AUTOSAR XML (schema 00046)
package /ComponentTypes
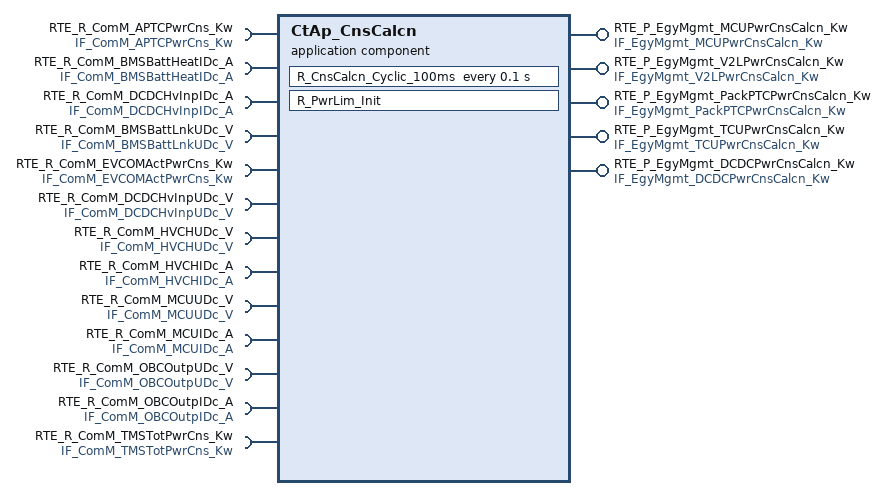
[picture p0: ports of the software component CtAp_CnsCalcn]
  application sw component type CtAp_CnsCalcn
    4 x provide port:
      RTE_P_EgyMgmt_MCUPwrCnsCalcn_Kw: nonqueued-sender-com-spec{data-element=tec_EgyMgmt_MCUPwrCnsCalcn_Kw, init-value=0}, provided-interface=IF_EgyMgmt_MCUPwrCnsCalcn_Kw
      RTE_P_EgyMgmt_V2LPwrCnsCalcn_Kw: nonqueued-sender-com-spec{data-element=IF_EgyMgmt_V2LPwrCnsCalcn_Kw, init-value=0}, provided-interface=IF_EgyMgmt_V2LPwrCnsCalcn_Kw
      RTE_P_EgyMgmt_PackPTCPwrCnsCalcn_Kw: nonqueued-sender-com-spec{data-element=tec_EgyMgmt_PackPTCPwrCnsCalcn_Kw, init-value=0}, provided-interface=IF_EgyMgmt_PackPTCPwrCnsCalcn_Kw
      RTE_P_EgyMgmt_TCUPwrCnsCalcn_Kw: nonqueued-sender-com-spec{data-element=tec_EgyMgmt_TCUPwrCnsCalcn_Kw, init-value=0}, provided-interface=IF_EgyMgmt_TCUPwrCnsCalcn_Kw
    13 x require port:
      RTE_R_ComM_APTCPwrCns_Kw: nonqueued-receiver-com-spec{data-element=tec_ComM_APTCPwrCns_Kw, filter=data-filter-type=ALWAYS, init-value=0}, required-interface=IF_ComM_APTCPwrCns_Kw
      RTE_R_ComM_BMSBattHeatIDc_A: nonqueued-receiver-com-spec{data-element=tec_ComM_BMSBattHeatIDc_A, filter=data-filter-type=ALWAYS, init-value=0}, required-interface=IF_ComM_BMSBattHeatIDc_A
      RTE_R_ComM_DCDCHvInpIDc_A: nonqueued-receiver-com-spec{data-element=tec_ComM_DCDCHvInpIDc_A, filter=data-filter-type=ALWAYS, init-value=0}, required-interface=IF_ComM_DCDCHvInpIDc_A
      RTE_R_ComM_BMSBattLnkUDc_V: nonqueued-receiver-com-spec{data-element=tec_ComM_BMSBattLnkUDc_V, filter=data-filter-type=ALWAYS, init-value=0}, required-interface=IF_ComM_BMSBattLnkUDc_V
      RTE_R_ComM_EVCOMActPwrCns_Kw: nonqueued-receiver-com-spec{data-element=tec_ComM_EVCOMActPwrCns_Kw, filter=data-filter-type=ALWAYS, init-value=0}, required-interface=IF_ComM_EVCOMActPwrCns_Kw
      RTE_R_ComM_DCDCHvInpUDc_V: nonqueued-receiver-com-spec{data-element=tec_ComM_DCDCHvInpUDc_V, filter=data-filter-type=ALWAYS, init-value=0}, required-interface=IF_ComM_DCDCHvInpUDc_V
      RTE_R_ComM_HVCHUDc_V: nonqueued-receiver-com-spec{data-element=tec_ComM_HVCHUDc_V, filter=data-filter-type=ALWAYS, init-value=0}, required-interface=IF_ComM_HVCHUDc_V
      RTE_R_ComM_HVCHIDc_A: nonqueued-receiver-com-spec{data-element=tec_ComM_HVCHIDc_A, filter=data-filter-type=ALWAYS, init-value=0}, required-interface=IF_ComM_HVCHIDc_A
      RTE_R_ComM_MCUUDc_V: nonqueued-receiver-com-spec{data-element=tec_ComM_MCUUDc_V, filter=data-filter-type=ALWAYS, init-value=0}, required-interface=IF_ComM_MCUUDc_V
      RTE_R_ComM_MCUIDc_A: nonqueued-receiver-com-spec{data-element=tec_ComM_MCUIDc_A, filter=data-filter-type=ALWAYS, init-value=0}, required-interface=IF_ComM_MCUIDc_A
      RTE_R_ComM_OBCOutpUDc_V: nonqueued-receiver-com-spec{data-element=tec_ComM_OBCOutpUDc_V, filter=data-filter-type=ALWAYS, init-value=0}, required-interface=IF_ComM_OBCOutpUDc_V
      RTE_R_ComM_OBCOutpIDc_A: nonqueued-receiver-com-spec{data-element=tec_ComM_OBCOutpIDc_A, filter=data-filter-type=ALWAYS, init-value=0}, required-interface=IF_ComM_OBCOutpIDc_A
      RTE_R_ComM_TMSTotPwrCns_Kw: nonqueued-receiver-com-spec{data-element=tec_ComM_TMSTotPwrCns_Kw, filter=data-filter-type=ALWAYS, init-value=0}, required-interface=IF_ComM_TMSTotPwrCns_Kw
    provide port RTE_P_EgyMgmt_DCDCPwrCnsCalcn_Kw: nonqueued-sender-com-spec{data-element=tec_EgyMgmt_DCDCPwrCnsCalcn_Kw, init-value=0}, provided-interface=IF_EgyMgmt_DCDCPwrCnsCalcn_Kw
    behavior CtAp_CnsCalcn_InternalBehavior
      init event CtAp_PwrLim_InitEvent: start-on-event=R_PwrLim_Init
      timing event TMT_R_CnsCalcn_Cyclic_100ms: start-on-event=R_CnsCalcn_Cyclic_100ms, period=0.1
      runnable R_PwrLim_Init
      runnable R_CnsCalcn_Cyclic_100ms
        data-receive-point-by-arguments:
          13 x access:
            REC_RTE_R_ComM_APTCPwrCns_Kw_tec_ComM_APTCPwrCns_Kw: accessed-variable=RTE_R_ComM_APTCPwrCns_Kw.tec_ComM_APTCPwrCns_Kw
            REC_RTE_R_ComM_BMSBattHeatIDc_A_tec_ComM_BMSBattHeatIDc_A: accessed-variable=RTE_R_ComM_BMSBattHeatIDc_A.tec_ComM_BMSBattHeatIDc_A
            REC_RTE_R_ComM_BMSBattLnkUDc_V_tec_ComM_BMSBattLnkUDc_V: accessed-variable=RTE_R_ComM_BMSBattLnkUDc_V.tec_ComM_BMSBattLnkUDc_V
            REC_RTE_R_ComM_DCDCHvInpIDc_A_tec_ComM_DCDCHvInpIDc_A: accessed-variable=RTE_R_ComM_DCDCHvInpIDc_A.tec_ComM_DCDCHvInpIDc_A
            REC_RTE_R_ComM_DCDCHvInpUDc_V_tec_ComM_DCDCHvInpUDc_V: accessed-variable=RTE_R_ComM_DCDCHvInpUDc_V.tec_ComM_DCDCHvInpUDc_V
            REC_RTE_R_ComM_EVCOMActPwrCns_Kw_tec_ComM_EVCOMActPwrCns_Kw: accessed-variable=RTE_R_ComM_EVCOMActPwrCns_Kw.tec_ComM_EVCOMActPwrCns_Kw
            REC_RTE_R_ComM_HVCHIDc_A_tec_ComM_HVCHIDc_A: accessed-variable=RTE_R_ComM_HVCHIDc_A.tec_ComM_HVCHIDc_A
            REC_RTE_R_ComM_HVCHUDc_V_tec_ComM_HVCHUDc_V: accessed-variable=RTE_R_ComM_HVCHUDc_V.tec_ComM_HVCHUDc_V
            REC_RTE_R_ComM_MCUIDc_A_tec_ComM_MCUIDc_A: accessed-variable=RTE_R_ComM_MCUIDc_A.tec_ComM_MCUIDc_A
            REC_RTE_R_ComM_MCUUDc_V_tec_ComM_MCUUDc_V: accessed-variable=RTE_R_ComM_MCUUDc_V.tec_ComM_MCUUDc_V
            REC_RTE_R_ComM_OBCOutpIDc_A_tec_ComM_OBCOutpIDc_A: accessed-variable=RTE_R_ComM_OBCOutpIDc_A.tec_ComM_OBCOutpIDc_A
            REC_RTE_R_ComM_OBCOutpUDc_V_tec_ComM_OBCOutpUDc_V: accessed-variable=RTE_R_ComM_OBCOutpUDc_V.tec_ComM_OBCOutpUDc_V
            REC_RTE_R_ComM_TMSTotPwrCns_Kw_tec_ComM_TMSTotPwrCns_Kw: accessed-variable=RTE_R_ComM_TMSTotPwrCns_Kw.tec_ComM_TMSTotPwrCns_Kw
        data-send-points:
          5 x access:
            SEND_RTE_P_EgyMgmt_DCDCPwrCnsCalcn_Kw_tec_EgyMgmt_DCDCPwrCnsCalcn_Kw: accessed-variable=RTE_P_EgyMgmt_DCDCPwrCnsCalcn_Kw.tec_EgyMgmt_DCDCPwrCnsCalcn_Kw
            SEND_RTE_P_EgyMgmt_MCUPwrCnsCalcn_Kw_tec_EgyMgmt_MCUPwrCnsCalcn_Kw: accessed-variable=RTE_P_EgyMgmt_MCUPwrCnsCalcn_Kw.tec_EgyMgmt_MCUPwrCnsCalcn_Kw
            SEND_RTE_P_EgyMgmt_PackPTCPwrCnsCalcn_Kw_tec_EgyMgmt_PackPTCPwrCnsCalcn_Kw: accessed-variable=RTE_P_EgyMgmt_PackPTCPwrCnsCalcn_Kw.tec_EgyMgmt_PackPTCPwrCnsCalcn_Kw
            SEND_RTE_P_EgyMgmt_TCUPwrCnsCalcn_Kw_tec_EgyMgmt_TCUPwrCnsCalcn_Kw: accessed-variable=RTE_P_EgyMgmt_TCUPwrCnsCalcn_Kw.tec_EgyMgmt_TCUPwrCnsCalcn_Kw
            SEND_RTE_P_EgyMgmt_V2LPwrCnsCalcn_Kw_IF_EgyMgmt_V2LPwrCnsCalcn_Kw: accessed-variable=RTE_P_EgyMgmt_V2LPwrCnsCalcn_Kw.IF_EgyMgmt_V2LPwrCnsCalcn_Kw
  swc implementation CtAp_CnsCalcn_Implementation: behavior=CtAp_CnsCalcn_InternalBehavior
    code-descriptors:
      code Default: artifact-descriptors=autosar-engineering-object=category=SWOBJ
